# GD32C231 register map
File version: 1.0
CPU: CM23 r0p0, little endian, MPU, FPU, 4 interrupt priority bits
Registers are 32-bit, read-write, reset 0x0 unless marked. A register's access mark holds for its fields unless they carry their own. Offsets are from the block's base; [hi:lo] are bit positions; {n}, {i} and the like mark numbered series.

## TIMER0 — Advanced-timers
Base 0x40012C00
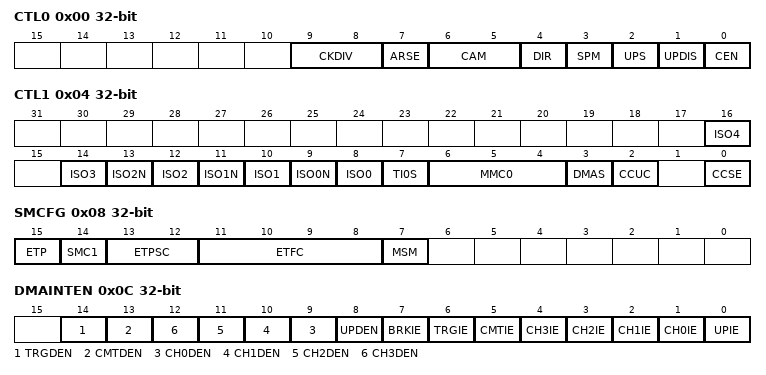
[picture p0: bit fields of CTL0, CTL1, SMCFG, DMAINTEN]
0x00 CTL0 — Control register 0
  [9:8] CKDIV — Clock division
  [7] ARSE — Auto-reload shadow enable
  [6:5] CAM — Counter align mode selection
  [4] DIR — Direction
  [3] SPM — Single pulse mode
  [2] UPS — Update source
  [1] UPDIS — Update disable
  [0] CEN — Counter enable
0x04 CTL1 — Control register 1
  [2n+8] ISO{n} (n=0..4) — Idle state of channel {n} output
  [13] ISO2N — Idle state of multi mode channel 2 complementary output
  [11] ISO1N — Idle state of multi mode channel 1 complementary output
  [9] ISO0N — Idle state of multi mode channel 0 complementary output
  [7] TI0S — Channel 0 trigger input selection
  [6:4] MMC0 — Master mode control
  [3] DMAS — DMA request source selection
  [2] CCUC — Commutation control shadow register update control
  [0] CCSE — Commutation control shadow enable
0x08 SMCFG — Slave mode configuration register
  [15] ETP — External trigger polarity
  [14] SMC1 — Part of SMC is used to enable external clock mode 1
  [13:12] ETPSC — External trigger prescaler
  [11:8] ETFC — External trigger filter control
  [7] MSM — Master-slave mode
0x0C DMAINTEN — DMA and interrupt enable register
  [14] TRGDEN — Trigger DMA request enable
  [13] CMTDEN — Commutation DMA request enable
  [n+9] CH{n}DEN (n=0..3) — Channel {n} capture/compare DMA request enable
  [8] UPDEN — Update DMA request enable
  [7] BRKIE — Break interrupt enable
  [6] TRGIE — Trigger interrupt enable
  [5] CMTIE — Commutation interrupt enable
  [n+1] CH{n}IE (n=0..3) — Channel {n} capture/compare interrupt enable
  [0] UPIE — Update interrupt enable
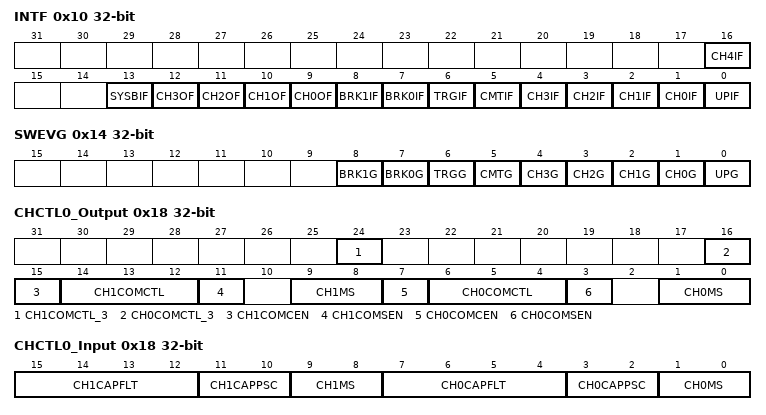
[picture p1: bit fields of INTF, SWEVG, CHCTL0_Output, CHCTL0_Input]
0x10 INTF — Interrupt flag register
  [16] CH4IF — Channel 4 capture/compare interrupt flag
  [13] SYSBIF — System source break interrupt flag
  [n+9] CH{n}OF (n=0..3) — Channel {n} over capture flag
  [8] BRK1IF — Break1 interrupt flag
  [7] BRK0IF — Break0 interrupt flag
  [6] TRGIF — Trigger interrupt flag
  [5] CMTIF — Channel commutation interrupt flag
  [n+1] CH{n}IF (n=0..3) — Channel {n} capture/compare interrupt flag
  [0] UPIF — Update interrupt flag
0x14 SWEVG wo — Software event generation register
  [8] BRK1G — BREAK1 event generation
  [7] BRK0G — Break0 event generation
  [6] TRGG — Trigger event generation
  [5] CMTG — Channel commutation event generation
  [n+1] CH{n}G (n=0..3) — Channel {n} capture or compare event generation
  [0] UPG — Update event generation
0x18 CHCTL0_Output — channel control register 0 (output mode)
  [24] CH1COMCTL_3 — Channel 1 compare output control
  [16] CH0COMCTL_3 — Channel 0 compare output control
  [15] CH1COMCEN — Channel 1 output compare clear enable
  [14:12] CH1COMCTL — Channel 1 compare output control
  [11] CH1COMSEN — Channel 1 output compare shadow enable
  [9:8] CH1MS — Channel 1 mode selection
  [7] CH0COMCEN — Channel 0 output compare clear enable
  [6:4] CH0COMCTL — Channel 0 compare output control
  [3] CH0COMSEN — Channel 0 compare output shadow enable
  [1:0] CH0MS — Channel 0 I/O mode selection
0x18 CHCTL0_Input (alternate view of CHCTL0_Output) — channel control register 0 (input mode)
  [15:12] CH1CAPFLT — Channel 1 input capture filter control
  [11:10] CH1CAPPSC — Channel 1 input capture prescaler
  [9:8] CH1MS — Channel 1 mode selection
  [7:4] CH0CAPFLT — Channel 0 input capture filter control
  [3:2] CH0CAPPSC — Channel 0 input capture prescaler
  [1:0] CH0MS — Channel 0 mode selection
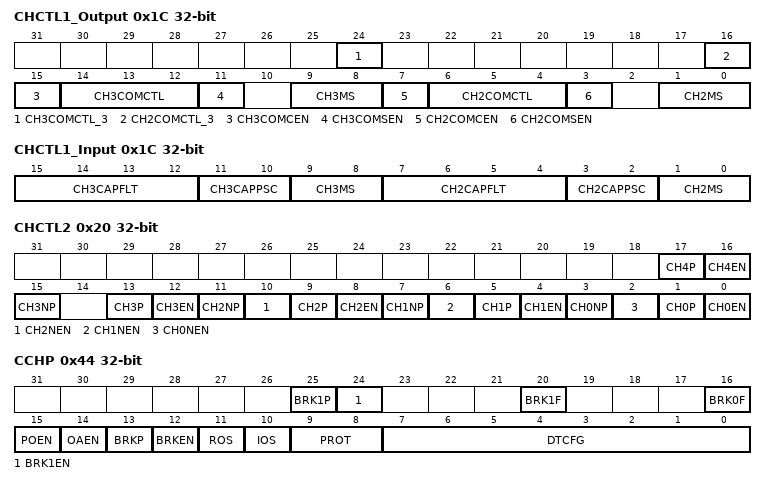
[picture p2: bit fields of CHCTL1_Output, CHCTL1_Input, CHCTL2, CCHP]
0x1C CHCTL1_Output — channel control register 1 (output mode)
  [24] CH3COMCTL_3 — Channel 3 compare output control
  [16] CH2COMCTL_3 — Channel 2 compare output control
  [15] CH3COMCEN — Channel 3 output compare clear enable
  [14:12] CH3COMCTL — Channel 3 compare output control
  [11] CH3COMSEN — Channel 3 output compare shadow enable
  [9:8] CH3MS — Channel 3 mode selection
  [7] CH2COMCEN — Channel 2 output compare clear enable
  [6:4] CH2COMCTL — Channel 2 compare output control
  [3] CH2COMSEN — Channel 2 compare output shadow enable
  [1:0] CH2MS — Channel 2 I/O mode selection
0x1C CHCTL1_Input (alternate view of CHCTL1_Output) — channel control register 1 (input mode)
  [15:12] CH3CAPFLT — Channel 3 input capture filter control
  [11:10] CH3CAPPSC — Channel 3 input capture prescaler
  [9:8] CH3MS — Channel 3 mode selection
  [7:4] CH2CAPFLT — Channel 2 input capture filter control
  [3:2] CH2CAPPSC — Channel 2 input capture prescaler
  [1:0] CH2MS — Channel 2 mode selection
0x20 CHCTL2 — Channel control register 2
  [4n+1] CH{n}P (n=0..4) — Channel {n} capture/compare function polarity
  [4n] CH{n}EN (n=0..4) — Channel {n} capture/compare function enable
  [15] CH3NP — Channel3 complementary output polarity
  [11] CH2NP — Channel 2 complementary output polarity
  [10] CH2NEN — Channel 2 complementary output enable
  [7] CH1NP — Channel 1 complementary output polarity
  [6] CH1NEN — Channel 1 complementary output enable
  [3] CH0NP — Channel 0 complementary output polarity
  [2] CH0NEN — Channel 0 complementary output enable
0x24 CNT — counter
  [15:0] CNT — current counter value
0x28 PSC — prescaler
  [15:0] PSC — Prescaler value of the counter clock
0x2C CAR — Counter auto reload register
  [15:0] CARL — Counter auto reload value
0x30 CREP — Counter repetition register
  [7:0] CREP — Counter repetition value
0x34 CH0CV — Channel 0 capture/compare value register
  [15:0] CH0VAL — Capture or compare value of channel0
0x38 CH1CV — Channel 1 capture/compare value register
  [15:0] CH1VAL — Capture or compare value of channel1
0x3C CH2CV — Channel 2 capture/compare value register
  [15:0] CH2VAL — Capture or compare value of channel 2
0x40 CH3CV — Channel 3 capture/compare value register
  [15:0] CH3VAL — Capture or compare value of channel 3
0x44 CCHP — channel complementary protection register
  [25] BRK1P — BREAK1 input signal polarity
  [24] BRK1EN — BREAK1 input signal enable
  [20] BRK1F — BREAK1 input signal filter
  [16] BRK0F — BREAK0 input signal filter
  [15] POEN — Primary output enable
  [14] OAEN — Output automatic enable
  [13] BRKP — BREAK input signal polarity
  [12] BRKEN — BREAK input signal enable
  [11] ROS — Run mode off-state configure
  [10] IOS — Idle mode off-state configure
  [9:8] PROT — Complementary register protect control
  [7:0] DTCFG — Dead time configure
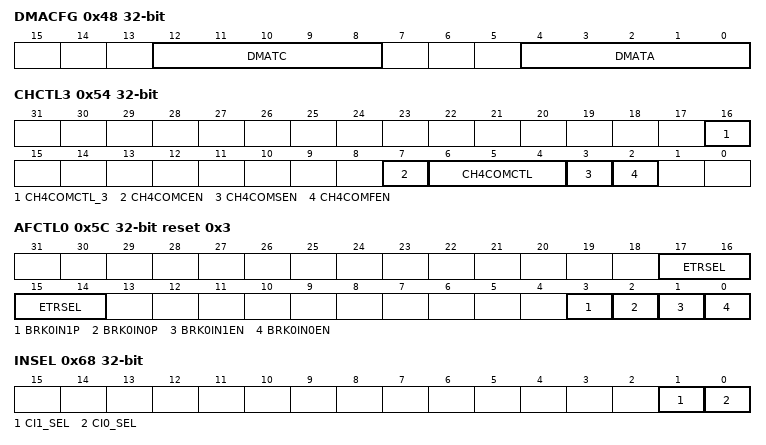
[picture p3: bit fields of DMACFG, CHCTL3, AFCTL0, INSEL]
0x48 DMACFG — DMA configuration register
  [12:8] DMATC — DMA transfer count
  [4:0] DMATA — DMA transfer access start address
0x4C DMATB — DMA transfer buffer register
  [15:0] DMATB — DMA transfer buffer
0x54 CHCTL3 — Channel control register 3
  [16] CH4COMCTL_3 — Channel 4 compare output control
  [7] CH4COMCEN — Channel 4 output compare clear enable
  [6:4] CH4COMCTL — Channel 4 compare output control
  [3] CH4COMSEN — Channel 4 compare output shadow enable
  [2] CH4COMFEN — Channel 4 output compare fast enable
0x58 CH4CV — Channel 4 capture/compare value register
  [15:0] CH4VAL — Write CHxVAL register selection
0x5C AFCTL0 reset 0x3 — TIMERx alternate function control register 0
  [17:14] ETRSEL — ETR source selection
  [3] BRK0IN1P — BREAK0 BRKIN1 alternate function input polarity
  [2] BRK0IN0P — BREAK0 BRKIN0 alternate function input polarity
  [1] BRK0IN1EN — BREAK0 BRKIN1 alternate function input enable
  [0] BRK0IN0EN — BREAK0 BRKIN0 alternate function input enable
0x68 INSEL — input selection register
  [1] CI1_SEL — TIMER0_CH1 input selection
  [0] CI0_SEL — TIMER0_CH0 input selection
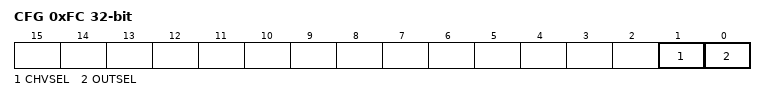
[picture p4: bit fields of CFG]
0xFC CFG — Configuration register
  [1] CHVSEL — Write CHxVAL register selection
  [0] OUTSEL — The output value selection
